VERSION ""

NS_ :

BS_:

BU_: XXX

BO_ 339 ASC_1: 8 XXX
 SG_ SPEED_KMH : 23|8@0+ (1,0) [0|1] "" XXX

BO_ 501 SZL_1: 8 XXX
 SG_ NEW_SIGNAL_1 : 7|16@0+ (0.045,0) [0|1] "" XXX
 SG_ NEW_SIGNAL_2 : 23|16@0+ (0.045,0) [0|1] "" XXX

BO_ 790 DME_1: 8 XXX
 SG_ ENGINE_RPM : 15|16@0+ (0.1,0) [0|65535] "" XXX

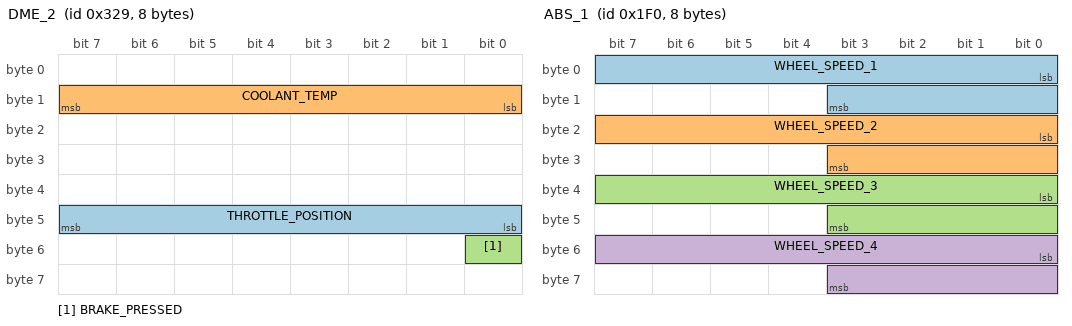
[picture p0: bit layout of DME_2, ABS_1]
BO_ 809 DME_2: 8 XXX
 SG_ THROTTLE_POSITION : 47|8@0+ (1,0) [0|1] "" XXX
 SG_ COOLANT_TEMP : 15|8@0+ (0.75,-49) [0|255] "" XXX
 SG_ BRAKE_PRESSED : 48|1@0+ (1,0) [0|1] "" XXX

BO_ 1349 DME_3: 8 XXX
 SG_ OIL_TEMP : 39|8@0+ (1,-48) [0|255] "" XXX

BO_ 1555 IKE_1: 8 XXX
 SG_ FUEL_LEVEL : 23|8@0+ (1,0) [0|255] "" XXX

BO_ 1557 IKE_2: 8 XXX
 SG_ OUTSIDE_TEMP : 31|8@0+ (1,0) [0|255] "" XXX

BO_ 496 ABS_1: 8 XXX
 SG_ WHEEL_SPEED_1 : 0|12@1+ (0.03125,0) [0|4095] "km/h" XXX
 SG_ WHEEL_SPEED_2 : 16|12@1+ (0.03125,0) [0|4095] "km/h" XXX
 SG_ WHEEL_SPEED_3 : 32|12@1+ (0.03125,0) [0|4095] "km/h" XXX
 SG_ WHEEL_SPEED_4 : 48|12@1+ (0.03125,0) [0|4095] "km/h" XXX

BO_ 499 STEERING_ANGLE_SENSOR: 8 XXX
 SG_ STEERING_VELOCITY : 31|16@0- (0.003125,0) [0|65535] "n/a" XXX
 SG_ ACTUAL_STEERING_ANGLE : 47|16@0+ (0.003125,-103.5) [0|1] "Degrees" XXX

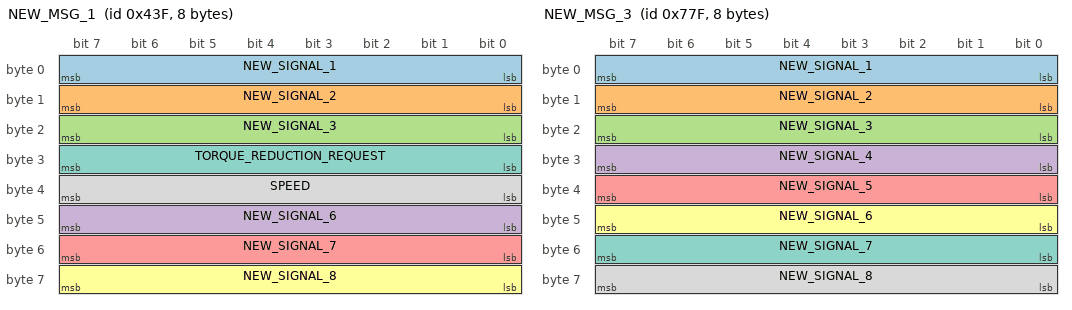
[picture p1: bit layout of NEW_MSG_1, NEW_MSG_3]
BO_ 1087 NEW_MSG_1: 8 XXX
 SG_ NEW_SIGNAL_1 : 7|8@0+ (1,0) [0|1] "" XXX
 SG_ NEW_SIGNAL_2 : 15|8@0+ (1,0) [0|1] "" XXX
 SG_ NEW_SIGNAL_3 : 23|8@0+ (1,0) [0|1] "" XXX
 SG_ NEW_SIGNAL_6 : 47|8@0+ (1,0) [0|1] "" XXX
 SG_ NEW_SIGNAL_7 : 55|8@0+ (1,0) [0|1] "" XXX
 SG_ NEW_SIGNAL_8 : 63|8@0+ (1,0) [0|1] "" XXX
 SG_ TORQUE_REDUCTION_REQUEST : 31|8@0+ (1,0) [0|1] "" XXX
 SG_ SPEED : 39|8@0+ (1,0) [0|1] "" XXX

BO_ 1916 NEW_MSG_2: 8 XXX
 SG_ NEW_SIGNAL_1 : 7|8@0+ (1,0) [0|1] "" XXX
 SG_ NEW_SIGNAL_2 : 15|8@0+ (1,0) [0|1] "" XXX
 SG_ NEW_SIGNAL_4 : 31|8@0+ (1,0) [0|1] "" XXX
 SG_ NEW_SIGNAL_6 : 47|8@0+ (1,0) [0|1] "" XXX
 SG_ NEW_SIGNAL_7 : 55|8@0+ (1,0) [0|1] "" XXX
 SG_ NEW_SIGNAL_5 : 39|8@0+ (1,0) [0|1] "" XXX
 SG_ NEW_SIGNAL_8 : 62|8@0+ (1,0) [0|1] "" XXX
 SG_ NEW_SIGNAL_3 : 23|8@0- (1,0) [0|1] "" XXX

BO_ 1919 NEW_MSG_3: 8 XXX
 SG_ NEW_SIGNAL_1 : 7|8@0+ (1,0) [0|1] "" XXX
 SG_ NEW_SIGNAL_2 : 15|8@0+ (1,0) [0|1] "" XXX
 SG_ NEW_SIGNAL_3 : 23|8@0+ (1,0) [0|1] "" XXX
 SG_ NEW_SIGNAL_4 : 31|8@0+ (1,0) [0|1] "" XXX
 SG_ NEW_SIGNAL_5 : 39|8@0+ (1,0) [0|1] "" XXX
 SG_ NEW_SIGNAL_6 : 47|8@0+ (1,0) [0|1] "" XXX
 SG_ NEW_SIGNAL_7 : 55|8@0+ (1,0) [0|1] "" XXX
 SG_ NEW_SIGNAL_8 : 63|8@0+ (1,0) [0|1] "" XXX

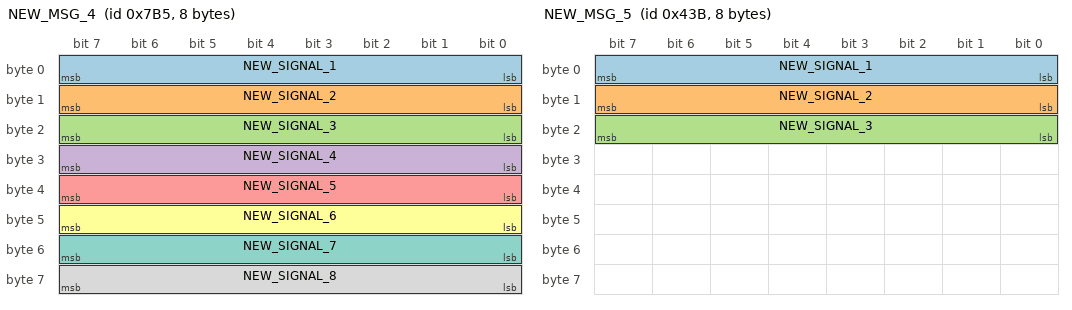
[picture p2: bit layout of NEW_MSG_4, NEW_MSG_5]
BO_ 1973 NEW_MSG_4: 8 XXX
 SG_ NEW_SIGNAL_1 : 7|8@0+ (1,0) [0|1] "" XXX
 SG_ NEW_SIGNAL_2 : 15|8@0+ (1,0) [0|1] "" XXX
 SG_ NEW_SIGNAL_3 : 23|8@0+ (1,0) [0|1] "" XXX
 SG_ NEW_SIGNAL_4 : 31|8@0+ (1,0) [0|1] "" XXX
 SG_ NEW_SIGNAL_5 : 39|8@0+ (1,0) [0|1] "" XXX
 SG_ NEW_SIGNAL_6 : 47|8@0+ (1,0) [0|1] "" XXX
 SG_ NEW_SIGNAL_7 : 55|8@0+ (1,0) [0|1] "" XXX
 SG_ NEW_SIGNAL_8 : 63|8@0+ (1,0) [0|1] "" XXX

BO_ 1083 NEW_MSG_5: 8 XXX
 SG_ NEW_SIGNAL_1 : 7|8@0+ (1,0) [0|1] "" XXX
 SG_ NEW_SIGNAL_2 : 15|8@0+ (1,0) [0|1] "" XXX
 SG_ NEW_SIGNAL_3 : 23|8@0+ (1,0) [0|1] "" XXX

CM_ SG_ 1555 FUEL_LEVEL "In liters";
CM_ SG_ 496 WHEEL_SPEED_1 "raw wheel speed";
CM_ SG_ 496 WHEEL_SPEED_2 "raw wheel speed";
CM_ SG_ 496 WHEEL_SPEED_3 "raw wheel speed";
CM_ SG_ 496 WHEEL_SPEED_4 "raw wheel speed";
CM_ SG_ 499 ACTUAL_STEERING_ANGLE "scaling not calibrated";
